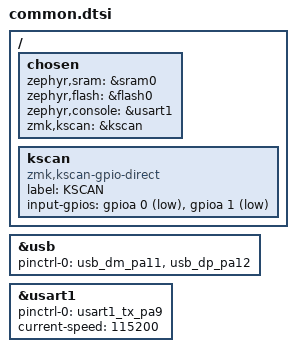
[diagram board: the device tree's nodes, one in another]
/*
 * Copyright (c) 2022 The ZMK Contributors
 * SPDX-License-Identifier: MIT
 */

/ {
	chosen {
		zephyr,sram = &sram0;
		zephyr,flash = &flash0;
		zephyr,console = &usart1;
		zmk,kscan = &kscan;
	};

	kscan: kscan {
		compatible = "zmk,kscan-gpio-direct";
		label = "KSCAN";
		input-gpios =
		    <&gpioa 0 (GPIO_ACTIVE_LOW | GPIO_PULL_UP)>,
		    <&gpioa 1 (GPIO_ACTIVE_LOW | GPIO_PULL_UP)>;
	};
};

&usb {
	pinctrl-0 = <&usb_dm_pa11 &usb_dp_pa12>;
	pinctrl-names = "default";
	status = "okay";
};

&usart1 {
	pinctrl-0 = <&usart1_tx_pa9>;
	pinctrl-names = "default";
	current-speed = <115200>;
	status = "okay";
};
